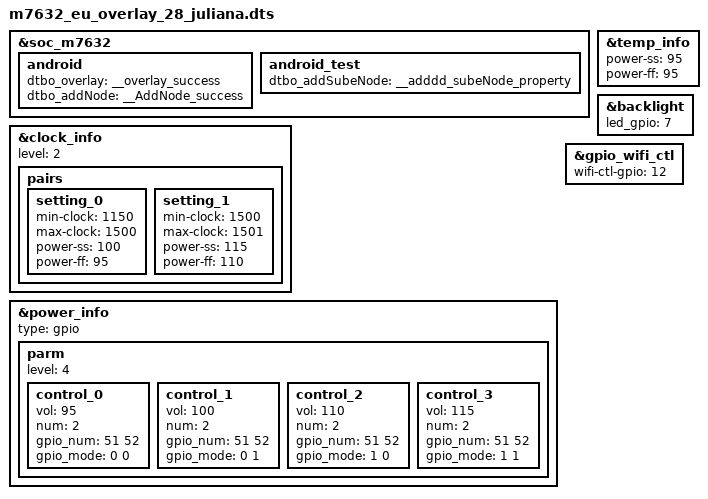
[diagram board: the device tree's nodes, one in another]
/dts-v1/;
/plugin/;

/ {
	fragment@0 {
		target = <&soc_m7632>;
		__overlay__ {
			android {
				dtbo_overlay = "__overlay_success";
				dtbo_addNode = "__AddNode_success";
			};
			android_test {
				dtbo_addSubeNode = "__adddd_subeNode_property";
			};
		};
	};


        fragment@1 {
		target = <&temp_info>;
		__overlay__ {
			power-ss = <95>;
			power-ff = <95>;
		};
	};

        fragment@2 {
                target = <&clock_info>;
                __overlay__ {
                        level = <2>;
                        pairs {
                                setting_0 {
                                        min-clock = <1150>;
                                        max-clock = <1500>;
                                        power-ss =  <100>;
                                        power-ff =  <95>;
                                };
                                setting_1 {
                                        min-clock = <1500>;
                                        max-clock = <1501>;
                                        power-ss =  <115>;
                                        power-ff =  <110>;
                                };
                        };
                };
        };

	fragment@3 {
	target = <&power_info>;
	__overlay__ {
			type = "gpio";
			parm {
				level = <4>;
				control_0 {
					vol = <95>;
					num = <2>;
					gpio_num =  <51 52>;
					gpio_mode = <0 0>;
				};
				control_1 {
					vol = <100>;
					num = <2>;
					gpio_num =  <51 52>;
					gpio_mode = <0 1>;
				};
				control_2 {
					vol = <110>;
					num = <2>;
					gpio_num =  <51 52>;
					gpio_mode = <1 0>;
				};
				control_3 {
					vol = <115>;
					num = <2>;
					gpio_num =  <51 52>;
					gpio_mode = <1 1>;
				};
			};
		};
	};

	fragment@4 {
		target = <&backlight>;
		__overlay__ {
			led_gpio = <7>;
		};
	};

        fragment@5 {
                target = <&gpio_wifi_ctl>;
                __overlay__ {
                        wifi-ctl-gpio = <12>;
                };
        };
};


